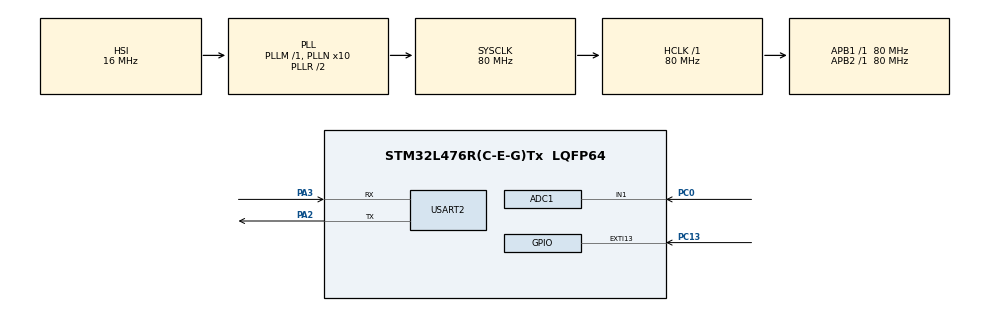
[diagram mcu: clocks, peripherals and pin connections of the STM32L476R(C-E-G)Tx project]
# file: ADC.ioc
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ADC1.Channel-0\#ChannelRegularConversion=ADC_CHANNEL_1
ADC1.DiscontinuousConvMode=ENABLE
ADC1.NbrOfConversionFlag=1
ADC1.OffsetNumber-0\#ChannelRegularConversion=ADC_OFFSET_NONE
ADC1.Rank-0\#ChannelRegularConversion=1
ADC1.SamplingTime-0\#ChannelRegularConversion=ADC_SAMPLETIME_2CYCLES_5
ADC1.master=1
Mcu.Family=STM32L4
Mcu.Name=STM32L476R(C-E-G)Tx
Mcu.Package=LQFP64
NVIC.EXTI15_10_IRQn=true\:0\:0\:false\:false\:true
NVIC.PriorityGroup=NVIC_PRIORITYGROUP_4
NVIC.RCC_IRQn=true\:0\:0\:false\:false\:true
PA2.Mode=Asynchronous
PA2.Signal=USART2_TX
PA3.Mode=Asynchronous
PA3.Signal=USART2_RX
PC0.Signal=ADCx_IN1
PC13.Signal=GPXTI13
PH0/OSC_IN.Mode=HSE-External-Oscillator
PH0/OSC_IN.Signal=RCC_OSC_IN
PH1/OSC_OUT.Mode=HSE-External-Oscillator
PH1/OSC_OUT.Signal=RCC_OSC_OUT
ProjectManager.HeapSize=0x200
ProjectManager.StackSize=0x400
ProjectManager.TargetToolchain=EWARM
RCC.ADCFreq_Value=64000000
RCC.AHBFreq_Value=80000000
RCC.APB1Freq_Value=80000000
RCC.APB1TimFreq_Value=80000000
RCC.APB2Freq_Value=80000000
RCC.APB2TimFreq_Value=80000000
RCC.CortexFreq_Value=80000000
RCC.HCLKFreq_Value=80000000
RCC.HSE_VALUE=8000000
RCC.HSI_VALUE=16000000
RCC.LSE_VALUE=32768
RCC.MSI_VALUE=4000000
RCC.PLLN=10
RCC.PLLSourceVirtual=RCC_PLLSOURCE_HSI
RCC.PREFETCH_ENABLE=1
RCC.SYSCLKFreq_VALUE=80000000
RCC.SYSCLKSource=RCC_SYSCLKSOURCE_PLLCLK
RCC.USBFreq_Value=64000000
RCC.VCOOutputFreq_Value=160000000
SH.ADCx_IN1.0=ADC1_IN1,IN1-Single-Ended
USART2.WordLength=UART_WORDLENGTH_8B
board=NUCLEO-L476RG

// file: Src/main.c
/**
  ******************************************************************************
  * File Name          : main.c
  * Description        : Main program body
  ******************************************************************************
  *
  * COPYRIGHT(c) 2017 STMicroelectronics
  *
  * Redistribution and use in source and binary forms, with or without modification,
  * are permitted provided that the following conditions are met:
  *   1. Redistributions of source code must retain the above copyright notice,
  *      this list of conditions and the following disclaimer.
  *   2. Redistributions in binary form must reproduce the above copyright notice,
  *      this list of conditions and the following disclaimer in the documentation
  *      and/or other materials provided with the distribution.
  *   3. Neither the name of STMicroelectronics nor the names of its contributors
  *      may be used to endorse or promote products derived from this software
  *      without specific prior written permission.
  *
  * THIS SOFTWARE IS PROVIDED BY THE COPYRIGHT HOLDERS AND CONTRIBUTORS "AS IS"
  * AND ANY EXPRESS OR IMPLIED WARRANTIES, INCLUDING, BUT NOT LIMITED TO, THE
  * IMPLIED WARRANTIES OF MERCHANTABILITY AND FITNESS FOR A PARTICULAR PURPOSE ARE
  * DISCLAIMED. IN NO EVENT SHALL THE COPYRIGHT HOLDER OR CONTRIBUTORS BE LIABLE
  * FOR ANY DIRECT, INDIRECT, INCIDENTAL, SPECIAL, EXEMPLARY, OR CONSEQUENTIAL
  * DAMAGES (INCLUDING, BUT NOT LIMITED TO, PROCUREMENT OF SUBSTITUTE GOODS OR
  * SERVICES; LOSS OF USE, DATA, OR PROFITS; OR BUSINESS INTERRUPTION) HOWEVER
  * CAUSED AND ON ANY THEORY OF LIABILITY, WHETHER IN CONTRACT, STRICT LIABILITY,
  * OR TORT (INCLUDING NEGLIGENCE OR OTHERWISE) ARISING IN ANY WAY OUT OF THE USE
  * OF THIS SOFTWARE, EVEN IF ADVISED OF THE POSSIBILITY OF SUCH DAMAGE.
  *
  ******************************************************************************
  */
#include "main.h"
#include "acquisitionDonnees.h"

  ADC_HandleTypeDef hadc1;
  UART_HandleTypeDef huart2;

/* USER CODE BEGIN PV */
/* Private variables ---------------------------------------------------------*/

   float poids; //variable qui rИcupere le poid en kg

/* USER CODE END PV */

void SystemClock_Config(void);
void Error_Handler(void);
static void MX_GPIO_Init(void);
static void MX_ADC1_Init(void);
static void MX_USART2_UART_Init(void);

/* USER CODE BEGIN PFP */
/* Private function prototypes -----------------------------------------------*/

/* USER CODE END PFP */

/* USER CODE BEGIN 0 */
/*float calculerPoids(){

    adcValeur=0;
    tension=0;
    poids=0.0;
    MoyennePoids =0.0;
    //printf("valeur de %f", MoyennePoids);
    sprintf(cool,"la variable cool a pour valeur : %f ", MoyennePoids);
    HAL_UART_Transmit(&huart2, cool, strlen(cool), 100);

    for(i=0;i<10;i++){
      HAL_ADC_Start(&hadc1);
      HAL_ADC_PollForConversion(&hadc1,100);
      adcValeur= HAL_ADC_GetValue(&hadc1);
      tabADC[i] = adcValeur;
      //tension=(adcValeur*2265)/3308;// pour 3.3v
      //tension=(adcValeur*2265)/4095; // pour 5v
      tension=(adcValeur*0.0012207031);// le plus proche
    //  tension=(adcValeur*0.00087890625);
      //tension=(adcValeur*0.0012207031)/4095;
     //poids = ((0.120882943620134*tension)+3.07870233495081);
     // poids = ((0.1186*tension)+3.079);
     // poids = ((0.120882943620134*tension)+3.07870233495081);
      poids = ((tension*100)/1.450191968);
      tabPoids[i] = poids;
      //HAL_Delay(1000);
      MoyennePoids = MoyennePoids + tabPoids[i];
    }
      MoyennePoids = (MoyennePoids/10);

      return (MoyennePoids);
}*/
/* USER CODE END 0 */

int main(void)
{

  /* MCU Configuration----------------------------------------------------------*/

  /* Reset of all peripherals, Initializes the Flash interface and the Systick. */
  HAL_Init();

  /* Configure the system clock */
  SystemClock_Config();

  /* Initialize all configured peripherals */
  MX_GPIO_Init();
  MX_ADC1_Init();
  MX_USART2_UART_Init();

  /* Infinite loop */
  while (1)
  {

      poids = getPoids();
  }

}

/** System Clock Configuration
*/
void SystemClock_Config(void)
{

  RCC_OscInitTypeDef RCC_OscInitStruct;
  RCC_ClkInitTypeDef RCC_ClkInitStruct;
  RCC_PeriphCLKInitTypeDef PeriphClkInit;

    /**Initializes the CPU, AHB and APB busses clocks
    */
  RCC_OscInitStruct.OscillatorType = RCC_OSCILLATORTYPE_HSI;
  RCC_OscInitStruct.HSIState = RCC_HSI_ON;
  RCC_OscInitStruct.HSICalibrationValue = 16;
  RCC_OscInitStruct.PLL.PLLState = RCC_PLL_ON;
  RCC_OscInitStruct.PLL.PLLSource = RCC_PLLSOURCE_HSI;
  RCC_OscInitStruct.PLL.PLLM = 1;
  RCC_OscInitStruct.PLL.PLLN = 10;
  RCC_OscInitStruct.PLL.PLLP = RCC_PLLP_DIV7;
  RCC_OscInitStruct.PLL.PLLQ = RCC_PLLQ_DIV2;
  RCC_OscInitStruct.PLL.PLLR = RCC_PLLR_DIV2;
  if (HAL_RCC_OscConfig(&RCC_OscInitStruct) != HAL_OK)
  {
    Error_Handler();
  }

    /**Initializes the CPU, AHB and APB busses clocks
    */
  RCC_ClkInitStruct.ClockType = RCC_CLOCKTYPE_HCLK|RCC_CLOCKTYPE_SYSCLK
                              |RCC_CLOCKTYPE_PCLK1|RCC_CLOCKTYPE_PCLK2;
  RCC_ClkInitStruct.SYSCLKSource = RCC_SYSCLKSOURCE_PLLCLK;
  RCC_ClkInitStruct.AHBCLKDivider = RCC_SYSCLK_DIV1;
  RCC_ClkInitStruct.APB1CLKDivider = RCC_HCLK_DIV1;
  RCC_ClkInitStruct.APB2CLKDivider = RCC_HCLK_DIV1;

  if (HAL_RCC_ClockConfig(&RCC_ClkInitStruct, FLASH_LATENCY_4) != HAL_OK)
  {
    Error_Handler();
  }

  PeriphClkInit.PeriphClockSelection = RCC_PERIPHCLK_USART2|RCC_PERIPHCLK_ADC;
  PeriphClkInit.Usart2ClockSelection = RCC_USART2CLKSOURCE_PCLK1;
  PeriphClkInit.AdcClockSelection = RCC_ADCCLKSOURCE_PLLSAI1;
  PeriphClkInit.PLLSAI1.PLLSAI1Source = RCC_PLLSOURCE_HSI;
  PeriphClkInit.PLLSAI1.PLLSAI1M = 1;
  PeriphClkInit.PLLSAI1.PLLSAI1N = 8;
  PeriphClkInit.PLLSAI1.PLLSAI1P = RCC_PLLP_DIV7;
  PeriphClkInit.PLLSAI1.PLLSAI1Q = RCC_PLLQ_DIV2;
  PeriphClkInit.PLLSAI1.PLLSAI1R = RCC_PLLR_DIV2;
  PeriphClkInit.PLLSAI1.PLLSAI1ClockOut = RCC_PLLSAI1_ADC1CLK;
  if (HAL_RCCEx_PeriphCLKConfig(&PeriphClkInit) != HAL_OK)
  {
    Error_Handler();
  }

    /**Configure the main internal regulator output voltage
    */
  if (HAL_PWREx_ControlVoltageScaling(PWR_REGULATOR_VOLTAGE_SCALE1) != HAL_OK)
  {
    Error_Handler();
  }

    /**Configure the Systick interrupt time
    */
  HAL_SYSTICK_Config(HAL_RCC_GetHCLKFreq()/1000);

    /**Configure the Systick
    */
  HAL_SYSTICK_CLKSourceConfig(SYSTICK_CLKSOURCE_HCLK);

  /* SysTick_IRQn interrupt configuration */
  HAL_NVIC_SetPriority(SysTick_IRQn, 0, 0);
}

/* ADC1 init function */
static void MX_ADC1_Init(void)
{

  ADC_MultiModeTypeDef multimode;
  ADC_ChannelConfTypeDef sConfig;

    /**Common config
    */
  hadc1.Instance = ADC1;
  hadc1.Init.ClockPrescaler = ADC_CLOCK_ASYNC_DIV1;
  hadc1.Init.Resolution = ADC_RESOLUTION_12B;
  hadc1.Init.DataAlign = ADC_DATAALIGN_RIGHT;
  hadc1.Init.ScanConvMode = ADC_SCAN_DISABLE;
  hadc1.Init.EOCSelection = ADC_EOC_SINGLE_CONV;
  hadc1.Init.LowPowerAutoWait = DISABLE;
  hadc1.Init.ContinuousConvMode = DISABLE;
  hadc1.Init.NbrOfConversion = 1;
  hadc1.Init.DiscontinuousConvMode = ENABLE;
  hadc1.Init.NbrOfDiscConversion = 1;
  hadc1.Init.ExternalTrigConv = ADC_SOFTWARE_START;
  hadc1.Init.ExternalTrigConvEdge = ADC_EXTERNALTRIGCONVEDGE_NONE;
  hadc1.Init.DMAContinuousRequests = DISABLE;
  hadc1.Init.Overrun = ADC_OVR_DATA_PRESERVED;
  hadc1.Init.OversamplingMode = DISABLE;
  if (HAL_ADC_Init(&hadc1) != HAL_OK)
  {
    Error_Handler();
  }

    /**Configure the ADC multi-mode
    */
  multimode.Mode = ADC_MODE_INDEPENDENT;
  if (HAL_ADCEx_MultiModeConfigChannel(&hadc1, &multimode) != HAL_OK)
  {
    Error_Handler();
  }

    /**Configure Regular Channel
    */
  sConfig.Channel = ADC_CHANNEL_1;
  sConfig.Rank = 1;
  sConfig.SamplingTime = ADC_SAMPLETIME_2CYCLES_5;
  sConfig.SingleDiff = ADC_SINGLE_ENDED;
  sConfig.OffsetNumber = ADC_OFFSET_NONE;
  sConfig.Offset = 0;
  if (HAL_ADC_ConfigChannel(&hadc1, &sConfig) != HAL_OK)
  {
    Error_Handler();
  }

}

/* USART2 init function */
static void MX_USART2_UART_Init(void)
{

  huart2.Instance = USART2;
  huart2.Init.BaudRate = 115200;
  huart2.Init.WordLength = UART_WORDLENGTH_8B;
  huart2.Init.StopBits = UART_STOPBITS_1;
  huart2.Init.Parity = UART_PARITY_NONE;
  huart2.Init.Mode = UART_MODE_TX_RX;
  huart2.Init.HwFlowCtl = UART_HWCONTROL_NONE;
  huart2.Init.OverSampling = UART_OVERSAMPLING_16;
  huart2.Init.OneBitSampling = UART_ONE_BIT_SAMPLE_DISABLE;
  huart2.AdvancedInit.AdvFeatureInit = UART_ADVFEATURE_NO_INIT;
  if (HAL_UART_Init(&huart2) != HAL_OK)
  {
    Error_Handler();
  }

}

/** Configure pins as
        * Analog
        * Input
        * Output
        * EVENT_OUT
        * EXTI
*/
static void MX_GPIO_Init(void)
{

  GPIO_InitTypeDef GPIO_InitStruct;

  /* GPIO Ports Clock Enable */
  __HAL_RCC_GPIOC_CLK_ENABLE();
  __HAL_RCC_GPIOH_CLK_ENABLE();
  __HAL_RCC_GPIOA_CLK_ENABLE();

  /*Configure GPIO pin : PC13 */
  GPIO_InitStruct.Pin = GPIO_PIN_13;
  GPIO_InitStruct.Mode = GPIO_MODE_IT_RISING;
  GPIO_InitStruct.Pull = GPIO_NOPULL;
  HAL_GPIO_Init(GPIOC, &GPIO_InitStruct);

  /* EXTI interrupt init*/
  HAL_NVIC_SetPriority(EXTI15_10_IRQn, 0, 0);
  HAL_NVIC_EnableIRQ(EXTI15_10_IRQn);

}

void Error_Handler(void)
{
  while(1)
  {
  }
}

/************************ (C) COPYRIGHT STMicroelectronics *****END OF FILE****/
